AUTOSAR XML (schema 4-0-3)
package /CalibrationComponents
  parameter sw component type SOHR: data-type-mapping=SOHR_CodeDataTypeMappingsSet
    provide port SOHR_Pport: provided-interface=SOHR_if
      provided-com-specs:
        init-value=57.900001525878906, parameter=KeSOHR_Ah_AvailableCapacityInst_MaxVal
        init-value=0, parameter=KeSOHR_Ah_AvailableCapacityInst_minVal
        init-value=57.900001525878906, parameter=KeSOHR_Ah_AvailableCapacity_MaxVal
        init-value=36.15999984741211, parameter=KeSOHR_Ah_AvailableCapacity_minVal
        init-value=0, parameter=KeSOHR_Ah_InitialAccumCharge
        init-value=0, parameter=KeSOHR_Ah_OvrdValue_AccumCharge
        init-value=57.900001525878906, parameter=KeSOHR_Ah_OvrdValue_AvailableCapacity
        init-value=57.900001525878906, parameter=KeSOHR_Ah_OvrdValue_AvailableCapacityInst
        init-value=5500, parameter=KeSOHR_Ah_UpdateIncrement
        init-value=100, parameter=KeSOHR_Pct_BatteryPackSOH_MaxVal
        init-value=80, parameter=KeSOHR_Pct_BatteryPackSOH_minVal
        init-value=80, parameter=KeSOHR_Pct_LowSOH_flt_Set
        init-value=100, parameter=KeSOHR_Pct_OvrdValue_BatteryPackSOH
        init-value=1, parameter=KeSOHR_t_LowSOH_flt_Set
        init-value=0, parameter=KeSOHR_b_LowSOH_flt_En
        init-value=0, parameter=KeSOHR_b_OvrdCond_AccumCharge
        init-value=0, parameter=KeSOHR_b_OvrdCond_AvailableCapacity
        init-value=0, parameter=KeSOHR_b_OvrdCond_AvailableCapacityInst
        init-value=0, parameter=KeSOHR_b_OvrdCond_BatteryPackSOH
        init-value=0, parameter=KeSOHR_b_SOHRank_En
        init-value=0, parameter=KeSOHR_k_LowSOH_flt_Val
        init-value=0, parameter=KeSOHR_k_SOHRank_Val
package /SOHR_Code_pkg/SOHR_Code_swc
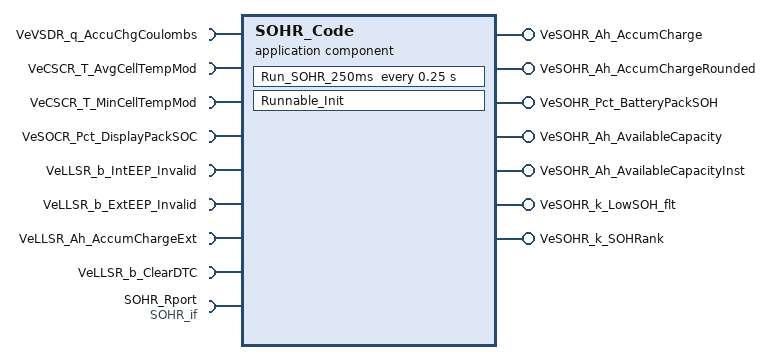
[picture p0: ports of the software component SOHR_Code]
  application sw component type SOHR_Code
    8 x require port:
      VeVSDR_q_AccuChgCoulombs: nonqueued-receiver-com-spec{data-element=VeVSDR_q_AccuChgCoulombs, init-value=0}, required-interface=VeVSDR_q_AccuChgCoulombs
      VeCSCR_T_AvgCellTempMod: nonqueued-receiver-com-spec{data-element=VeCSCR_T_AvgCellTempMod, init-value=0}, required-interface=VeCSCR_T_AvgCellTempMod
      VeCSCR_T_MinCellTempMod: nonqueued-receiver-com-spec{data-element=VeCSCR_T_MinCellTempMod, init-value=0}, required-interface=VeCSCR_T_MinCellTempMod
      VeSOCR_Pct_DisplayPackSOC: nonqueued-receiver-com-spec{data-element=VeSOCR_Pct_DisplayPackSOC, init-value=0}, required-interface=VeSOCR_Pct_DisplayPackSOC
      VeLLSR_b_IntEEP_Invalid: nonqueued-receiver-com-spec{data-element=VeLLSR_b_IntEEP_Invalid, init-value=0}, required-interface=VeLLSR_b_IntEEP_Invalid
      VeLLSR_b_ExtEEP_Invalid: nonqueued-receiver-com-spec{data-element=VeLLSR_b_ExtEEP_Invalid, init-value=0}, required-interface=VeLLSR_b_ExtEEP_Invalid
      VeLLSR_Ah_AccumChargeExt: nonqueued-receiver-com-spec{data-element=VeLLSR_Ah_AccumChargeExt, init-value=0}, required-interface=VeLLSR_Ah_AccumChargeExt
      VeLLSR_b_ClearDTC: nonqueued-receiver-com-spec{data-element=VeLLSR_b_ClearDTC, init-value=0}, required-interface=VeLLSR_b_ClearDTC
    7 x provide port:
      VeSOHR_Ah_AccumCharge: nonqueued-sender-com-spec{data-element=VeSOHR_Ah_AccumCharge, init-value=0}, provided-interface=VeSOHR_Ah_AccumCharge
      VeSOHR_Ah_AccumChargeRounded: nonqueued-sender-com-spec{data-element=VeSOHR_Ah_AccumChargeRounded, init-value=0}, provided-interface=VeSOHR_Ah_AccumChargeRounded
      VeSOHR_Pct_BatteryPackSOH: nonqueued-sender-com-spec{data-element=VeSOHR_Pct_BatteryPackSOH, init-value=0}, provided-interface=VeSOHR_Pct_BatteryPackSOH
      VeSOHR_Ah_AvailableCapacity: nonqueued-sender-com-spec{data-element=VeSOHR_Ah_AvailableCapacity, init-value=0}, provided-interface=VeSOHR_Ah_AvailableCapacity
      VeSOHR_Ah_AvailableCapacityInst: nonqueued-sender-com-spec{data-element=VeSOHR_Ah_AvailableCapacityInst, init-value=0}, provided-interface=VeSOHR_Ah_AvailableCapacityInst
      VeSOHR_k_LowSOH_flt: nonqueued-sender-com-spec{data-element=VeSOHR_k_LowSOH_flt, init-value=0}, provided-interface=VeSOHR_k_LowSOH_flt
      VeSOHR_k_SOHRank: nonqueued-sender-com-spec{data-element=VeSOHR_k_SOHRank, init-value=0}, provided-interface=VeSOHR_k_SOHRank
    require port SOHR_Rport: required-interface=SOHR_if
    behavior SOHR_Code: constant-value-mapping=SOHR_Code_datatype_AVS_MappingSet, data-type-mapping=SOHR_CodeDataTypeMappingsSet, handle-termination-and-restart=NO-SUPPORT
      exclusive area EA_NeSOHR_Ah_AccumCharge
      timing event Event_Run_SOHR_250ms: start-on-event=Run_SOHR_250ms, period=0.25
      per instance memory NeSOHR_Ah_AccumCharge: implementation-data-type=Float, type=NeSOHR_Ah_AccumCharge_Float, type-definition=Float
      runnable Runnable_Init: symbol=SOHR_Code_Init
      runnable Run_SOHR_250ms: runs-inside-exclusive-area=EA_NeSOHR_Ah_AccumCharge
        data-read-access:
          8 x access:
            IN_VeCSCR_T_AvgCellTempMod_VeCSCR_T_AvgCellTempMod: accessed-variable=VeCSCR_T_AvgCellTempMod.VeCSCR_T_AvgCellTempMod
            IN_VeCSCR_T_MinCellTempMod_VeCSCR_T_MinCellTempMod: accessed-variable=VeCSCR_T_MinCellTempMod.VeCSCR_T_MinCellTempMod
            IN_VeLLSR_Ah_AccumChargeExt_VeLLSR_Ah_AccumChargeExt: accessed-variable=VeLLSR_Ah_AccumChargeExt.VeLLSR_Ah_AccumChargeExt
            IN_VeLLSR_b_ClearDTC_VeLLSR_b_ClearDTC: accessed-variable=VeLLSR_b_ClearDTC.VeLLSR_b_ClearDTC
            IN_VeLLSR_b_ExtEEP_Invalid_VeLLSR_b_ExtEEP_Invalid: accessed-variable=VeLLSR_b_ExtEEP_Invalid.VeLLSR_b_ExtEEP_Invalid
            IN_VeLLSR_b_IntEEP_Invalid_VeLLSR_b_IntEEP_Invalid: accessed-variable=VeLLSR_b_IntEEP_Invalid.VeLLSR_b_IntEEP_Invalid
            IN_VeSOCR_Pct_DisplayPackSOC_VeSOCR_Pct_DisplayPackSOC: accessed-variable=VeSOCR_Pct_DisplayPackSOC.VeSOCR_Pct_DisplayPackSOC
            IN_VeVSDR_q_AccuChgCoulombs_VeVSDR_q_AccuChgCoulombs: accessed-variable=VeVSDR_q_AccuChgCoulombs.VeVSDR_q_AccuChgCoulombs
        data-send-points:
          7 x access:
            OUT_VeSOHR_Ah_AccumCharge_VeSOHR_Ah_AccumCharge: accessed-variable=VeSOHR_Ah_AccumCharge.VeSOHR_Ah_AccumCharge
            OUT_VeSOHR_Ah_AccumChargeRounded_VeSOHR_Ah_AccumChargeRounded: accessed-variable=VeSOHR_Ah_AccumChargeRounded.VeSOHR_Ah_AccumChargeRounded
            OUT_VeSOHR_Pct_BatteryPackSOH_VeSOHR_Pct_BatteryPackSOH: accessed-variable=VeSOHR_Pct_BatteryPackSOH.VeSOHR_Pct_BatteryPackSOH
            OUT_VeSOHR_Ah_AvailableCapacity_VeSOHR_Ah_AvailableCapacity: accessed-variable=VeSOHR_Ah_AvailableCapacity.VeSOHR_Ah_AvailableCapacity
            OUT_VeSOHR_Ah_AvailableCapacityInst_VeSOHR_Ah_4116f3b1f2bf6fcd: accessed-variable=VeSOHR_Ah_AvailableCapacityInst.VeSOHR_Ah_AvailableCapacityInst
            OUT_VeSOHR_k_LowSOH_flt_VeSOHR_k_LowSOH_flt: accessed-variable=VeSOHR_k_LowSOH_flt.VeSOHR_k_LowSOH_flt
            OUT_VeSOHR_k_SOHRank_VeSOHR_k_SOHRank: accessed-variable=VeSOHR_k_SOHRank.VeSOHR_k_SOHRank
        23 x parameter access:
          CALPRM_SOHR_Rport_KeSOHR_Ah_AvailableCapacityInst_MaxVal: accessed-parameter=SOHR_Rport.KeSOHR_Ah_AvailableCapacityInst_MaxVal
          CALPRM_SOHR_Rport_KeSOHR_Ah_AvailableCapacityInst_minVal: accessed-parameter=SOHR_Rport.KeSOHR_Ah_AvailableCapacityInst_minVal
          CALPRM_SOHR_Rport_KeSOHR_Ah_AvailableCapacity_MaxVal: accessed-parameter=SOHR_Rport.KeSOHR_Ah_AvailableCapacity_MaxVal
          CALPRM_SOHR_Rport_KeSOHR_Ah_AvailableCapacity_minVal: accessed-parameter=SOHR_Rport.KeSOHR_Ah_AvailableCapacity_minVal
          CALPRM_SOHR_Rport_KeSOHR_Ah_OvrdValue_AccumCharge: accessed-parameter=SOHR_Rport.KeSOHR_Ah_OvrdValue_AccumCharge
          CALPRM_SOHR_Rport_KeSOHR_Ah_OvrdValue_AvailableCapacity: accessed-parameter=SOHR_Rport.KeSOHR_Ah_OvrdValue_AvailableCapacity
          CALPRM_SOHR_Rport_KeSOHR_Ah_OvrdValue_AvailableCapacityInst: accessed-parameter=SOHR_Rport.KeSOHR_Ah_OvrdValue_AvailableCapacityInst
          CALPRM_SOHR_Rport_KeSOHR_Ah_UpdateIncrement: accessed-parameter=SOHR_Rport.KeSOHR_Ah_UpdateIncrement
          CALPRM_SOHR_Rport_KeSOHR_Pct_BatteryPackSOH_MaxVal: accessed-parameter=SOHR_Rport.KeSOHR_Pct_BatteryPackSOH_MaxVal
          CALPRM_SOHR_Rport_KeSOHR_Pct_BatteryPackSOH_minVal: accessed-parameter=SOHR_Rport.KeSOHR_Pct_BatteryPackSOH_minVal
          CALPRM_SOHR_Rport_KeSOHR_Pct_LowSOH_flt_Set: accessed-parameter=SOHR_Rport.KeSOHR_Pct_LowSOH_flt_Set
          CALPRM_SOHR_Rport_KeSOHR_Pct_OvrdValue_BatteryPackSOH: accessed-parameter=SOHR_Rport.KeSOHR_Pct_OvrdValue_BatteryPackSOH
          CALPRM_SOHR_Rport_KeSOHR_b_LowSOH_flt_En: accessed-parameter=SOHR_Rport.KeSOHR_b_LowSOH_flt_En
          CALPRM_SOHR_Rport_KeSOHR_b_OvrdCond_AccumCharge: accessed-parameter=SOHR_Rport.KeSOHR_b_OvrdCond_AccumCharge
          CALPRM_SOHR_Rport_KeSOHR_b_OvrdCond_AvailableCapacity: accessed-parameter=SOHR_Rport.KeSOHR_b_OvrdCond_AvailableCapacity
          CALPRM_SOHR_Rport_KeSOHR_b_OvrdCond_AvailableCapacityInst: accessed-parameter=SOHR_Rport.KeSOHR_b_OvrdCond_AvailableCapacityInst
          CALPRM_SOHR_Rport_KeSOHR_b_OvrdCond_BatteryPackSOH: accessed-parameter=SOHR_Rport.KeSOHR_b_OvrdCond_BatteryPackSOH
          CALPRM_SOHR_Rport_KeSOHR_b_SOHRank_En: accessed-parameter=SOHR_Rport.KeSOHR_b_SOHRank_En
          CALPRM_SOHR_Rport_KeSOHR_k_LowSOH_flt_Val: accessed-parameter=SOHR_Rport.KeSOHR_k_LowSOH_flt_Val
          CALPRM_SOHR_Rport_KeSOHR_k_SOHRank_Val: accessed-parameter=SOHR_Rport.KeSOHR_k_SOHRank_Val
          CALPRM_SOHR_Rport_KeSOHR_t_LowSOH_flt_Set: accessed-parameter=SOHR_Rport.KeSOHR_t_LowSOH_flt_Set
          SCALPRM_KtSOHR_r_SOHCoefficient_Table: accessed-parameter=KtSOHR_r_SOHCoefficient_Table, sw-calprm-axis-set={sw-axis-index=1, sw-axis-grouped=ar-parameter=KxSOHR_r_SOHCoefficient}
          SCALPRM_KxSOHR_r_SOHCoefficient: accessed-parameter=KxSOHR_r_SOHCoefficient
      swc service dependency SwcNv_NeSOHR_Ah_AccumCharge: assigned-datas=role-based-data-assignment={role=ramBlock, used-pim=NeSOHR_Ah_AccumCharge}
        service-needs:
          nv block needs SwcNv_NeSOHR_Ah_AccumCharge: restore-at-start=true, store-at-shutdown=true
      shared-parameters:
        parameter data prototype KtSOHR_r_SOHCoefficient_Table: category=CURVE, sw-calibration-access=READ-WRITE, type=Appl_KtSOHR_r_SOHCoefficient_Table, init-value=constant-reference={short-label=KtSOHR_r_SOHCoefficient_Table, constant=KtSOHR_r_SOHCoefficient_Table}
        parameter data prototype KxSOHR_r_SOHCoefficient: category=COM_AXIS, sw-calibration-access=READ-WRITE, type=Appl_KxSOHR_r_SOHCoefficient, init-value=constant-reference={short-label=KxSOHR_r_SOHCoefficient, constant=KxSOHR_r_SOHCoefficient}
